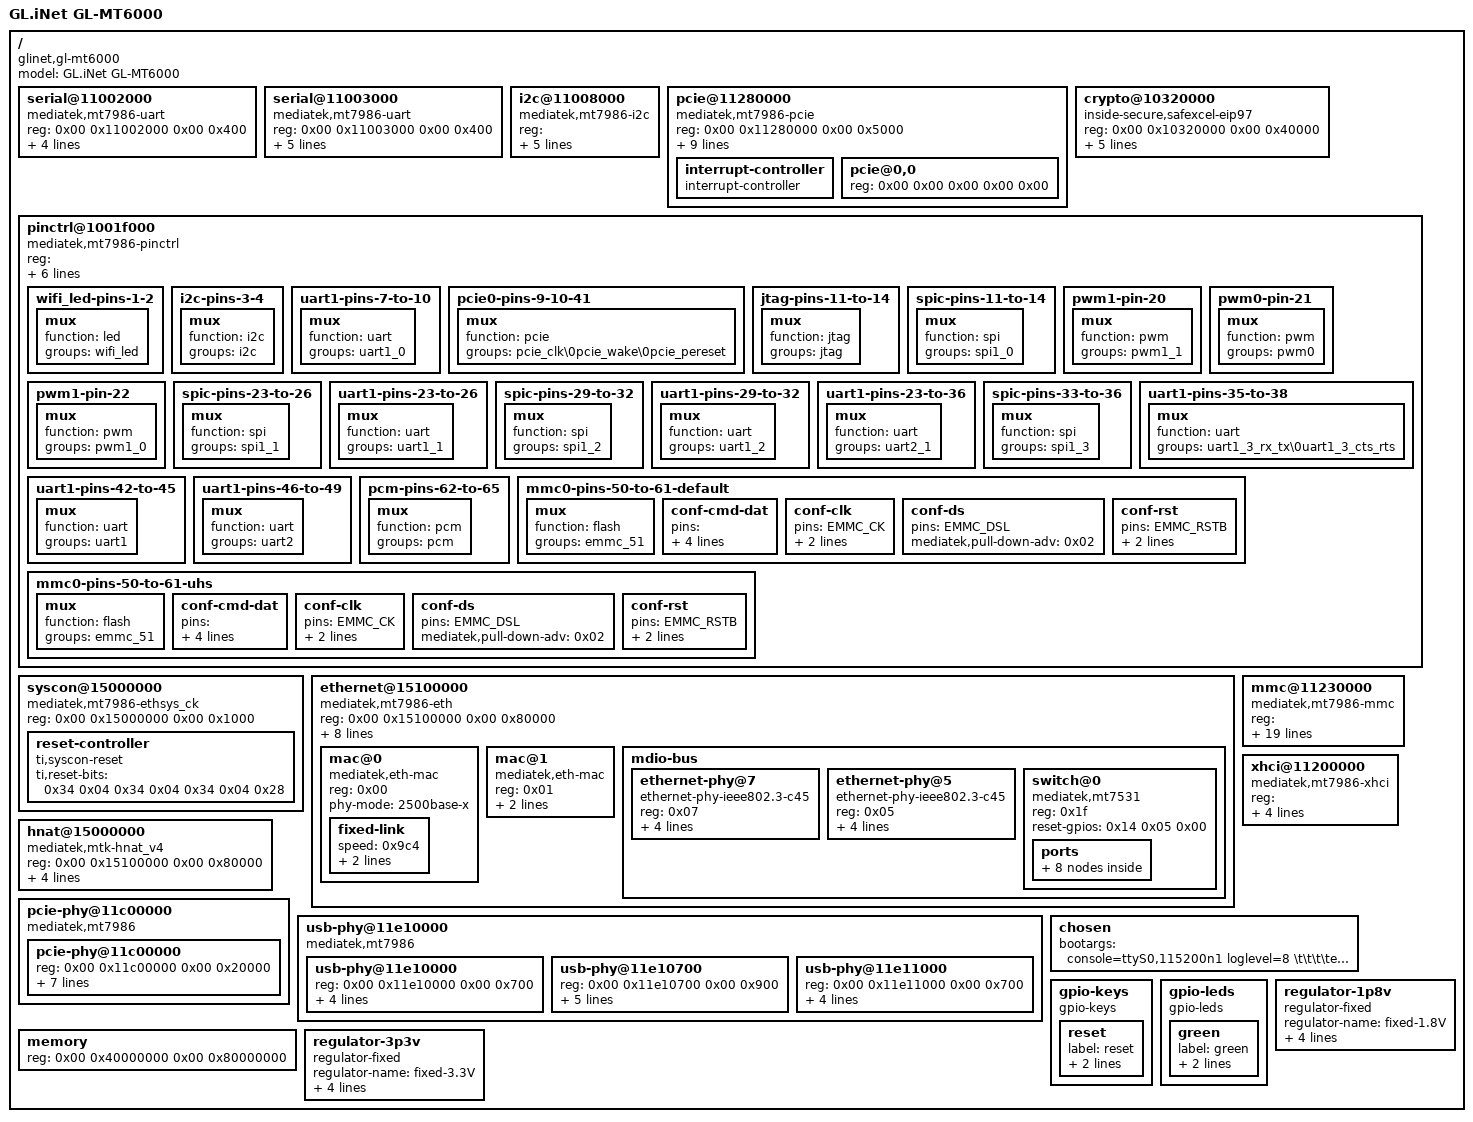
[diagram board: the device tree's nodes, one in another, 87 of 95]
/dts-v1/;
#include <dt-bindings/gpio/gpio.h>     
#include <dt-bindings/input/input.h>   
#include <dt-bindings/pinctrl/mt65xx.h>
                                       
#include "mt7986a.dtsi"                

  
/ {
	model = "GL.iNet GL-MT6000";
	compatible = "glinet,gl-mt6000", "mediatek,mt7986a";

	serial@11002000 {
		compatible = "mediatek,mt7986-uart\0mediatek,mt6577-uart";
		reg = <0x00 0x11002000 0x00 0x400>;
		interrupts = <0x00 0x7b 0x04>;
		clocks = <0x04 0x1c>;
		assigned-clocks = <0x05 0x3b 0x04 0x00>;
		assigned-clock-parents = <0x05 0x00 0x03 0x01>;
		status = "okay";
	};

	serial@11003000 {
		compatible = "mediatek,mt7986-uart\0mediatek,mt6577-uart";
		reg = <0x00 0x11003000 0x00 0x400>;
		interrupts = <0x00 0x7c 0x04>;
		clocks = <0x04 0x1d>;
		assigned-clocks = <0x04 0x01>;
		assigned-clock-parents = <0x03 0x00>;
		status = "okay";
		pinctrl-names = "default";
		pinctrl-0 = <0x07>;
	};

	i2c@11008000 {
		compatible = "mediatek,mt7986-i2c";
		reg = <0x00 0x11008000 0x00 0x90 0x00 0x10217080 0x00 0x80>;
		interrupts = <0x00 0x88 0x04>;
		clock-div = <0x05>;
		clocks = <0x04 0x1b 0x04 0x17>;
		clock-names = "main\0dma";
		#address-cells = <0x01>;
		#size-cells = <0x00>;
		status = "okay";
		pinctrl-names = "default";
		pinctrl-0 = <0x08>;
	};

	pcie@11280000 {
		compatible = "mediatek,mt7986-pcie";
		reg = <0x00 0x11280000 0x00 0x5000>;
		reg-names = "pcie-mac";
		#address-cells = <0x03>;
		#size-cells = <0x02>;
		interrupts = <0x00 0xa8 0x04>;
		bus-range = <0x00 0xff>;
		ranges = <0x82000000 0x00 0x20000000 0x00 0x20000000 0x00 0x10000000>;
		status = "okay";
		clocks = <0x04 0x08 0x04 0x32 0x04 0x33 0x04 0x34 0x04 0x35>;
		phys = <0x11 0x02>;
		phy-names = "pcie-phy";
		#interrupt-cells = <0x01>;
		interrupt-map-mask = <0x00 0x00 0x00 0x07>;
		interrupt-map = <0x00 0x00 0x00 0x01 0x12 0x00 0x00 0x00 0x00 0x02 0x12 0x01 0x00 0x00 0x00 0x03 0x12 0x02 0x00 0x00 0x00 0x04 0x12 0x03>;
		pinctrl-names = "default";
		pinctrl-0 = <0x13>;

		interrupt-controller {
			interrupt-controller;
			#address-cells = <0x00>;
			#interrupt-cells = <0x01>;
			phandle = <0x12>;
		};

		pcie@0,0 {
			reg = <0x00 0x00 0x00 0x00 0x00>;
		};
	};

	crypto@10320000 {
		compatible = "inside-secure,safexcel-eip97";
		reg = <0x00 0x10320000 0x00 0x40000>;
		interrupts = <0x00 0x74 0x04 0x00 0x75 0x04 0x00 0x76 0x04 0x00 0x77 0x04>;
		interrupt-names = "ring0\0ring1\0ring2\0ring3";
		clocks = <0x04 0x0f>;
		clock-names = "infra_eip97_ck";
		assigned-clocks = <0x05 0x50>;
		assigned-clock-parents = <0x05 0x15>;
	};

	pinctrl@1001f000 {
		compatible = "mediatek,mt7986-pinctrl";
		reg = <0x00 0x1001f000 0x00 0x1000 0x00 0x11c30000 0x00 0x1000 0x00 0x11c40000 0x00 0x1000 0x00 0x11e20000 0x00 0x1000 0x00 0x11e30000 0x00 0x1000 0x00 0x11f00000 0x00 0x1000 0x00 0x11f10000 0x00 0x1000 0x00 0x1000b000 0x00 0x1000>;
		reg-names = "gpio_base\0iocfg_rt_base\0iocfg_rb_base\0iocfg_lt_base\0iocfg_lb_base\0iocfg_tr_base\0iocfg_tl_base\0eint";
		gpio-controller;
		#gpio-cells = <0x02>;
		gpio-ranges = <0x14 0x00 0x00 0x64>;
		interrupt-controller;
		interrupts = <0x00 0xe1 0x04>;
		interrupt-parent = <0x01>;
		#interrupt-cells = <0x02>;
		phandle = <0x14>;

		wifi_led-pins-1-2 {

			mux {
				function = "led";
				groups = "wifi_led";
			};
		};

		i2c-pins-3-4 {
			phandle = <0x08>;

			mux {
				function = "i2c";
				groups = "i2c";
			};
		};

		uart1-pins-7-to-10 {

			mux {
				function = "uart";
				groups = "uart1_0";
			};
		};

		pcie0-pins-9-10-41 {
			phandle = <0x13>;

			mux {
				function = "pcie";
				groups = "pcie_clk\0pcie_wake\0pcie_pereset";
			};
		};

		jtag-pins-11-to-14 {

			mux {
				function = "jtag";
				groups = "jtag";
			};
		};

		spic-pins-11-to-14 {

			mux {
				function = "spi";
				groups = "spi1_0";
			};
		};

		pwm1-pin-20 {

			mux {
				function = "pwm";
				groups = "pwm1_1";
			};
		};

		pwm0-pin-21 {
			phandle = <0x06>;

			mux {
				function = "pwm";
				groups = "pwm0";
			};
		};

		pwm1-pin-22 {

			mux {
				function = "pwm";
				groups = "pwm1_0";
			};
		};

		spic-pins-23-to-26 {

			mux {
				function = "spi";
				groups = "spi1_1";
			};
		};

		uart1-pins-23-to-26 {

			mux {
				function = "uart";
				groups = "uart1_1";
			};
		};

		spic-pins-29-to-32 {
			phandle = <0x1d>;

			mux {
				function = "spi";
				groups = "spi1_2";
			};
		};

		uart1-pins-29-to-32 {

			mux {
				function = "uart";
				groups = "uart1_2";
			};
		};

		uart1-pins-23-to-36 {

			mux {
				function = "uart";
				groups = "uart2_1";
			};
		};

		spic-pins-33-to-36 {

			mux {
				function = "spi";
				groups = "spi1_3";
			};
		};

		uart1-pins-35-to-38 {

			mux {
				function = "uart";
				groups = "uart1_3_rx_tx\0uart1_3_cts_rts";
			};
		};

		uart1-pins-42-to-45 {
			phandle = <0x07>;

			mux {
				function = "uart";
				groups = "uart1";
			};
		};

		uart1-pins-46-to-49 {

			mux {
				function = "uart";
				groups = "uart2";
			};
		};

		pcm-pins-62-to-65 {

			mux {
				function = "pcm";
				groups = "pcm";
			};
		};

		mmc0-pins-50-to-61-default {
			phandle = <0x1e>;

			mux {
				function = "flash";
				groups = "emmc_51";
			};

			conf-cmd-dat {
				pins = "EMMC_DATA_0\0EMMC_DATA_1\0EMMC_DATA_2\0EMMC_DATA_3\0EMMC_DATA_4\0EMMC_DATA_5\0EMMC_DATA_6\0EMMC_DATA_7\0EMMC_CMD";
				input-enable;
				drive-strength = <0x04>;
				mediatek,pull-up-adv = <0x01>;
			};

			conf-clk {
				pins = "EMMC_CK";
				drive-strength = <0x06>;
				mediatek,pull-down-adv = <0x02>;
			};

			conf-ds {
				pins = "EMMC_DSL";
				mediatek,pull-down-adv = <0x02>;
			};

			conf-rst {
				pins = "EMMC_RSTB";
				drive-strength = <0x04>;
				mediatek,pull-up-adv = <0x01>;
			};
		};

		mmc0-pins-50-to-61-uhs {
			phandle = <0x1f>;

			mux {
				function = "flash";
				groups = "emmc_51";
			};

			conf-cmd-dat {
				pins = "EMMC_DATA_0\0EMMC_DATA_1\0EMMC_DATA_2\0EMMC_DATA_3\0EMMC_DATA_4\0EMMC_DATA_5\0EMMC_DATA_6\0EMMC_DATA_7\0EMMC_CMD";
				input-enable;
				drive-strength = <0x04>;
				mediatek,pull-up-adv = <0x01>;
			};

			conf-clk {
				pins = "EMMC_CK";
				drive-strength = <0x06>;
				mediatek,pull-down-adv = <0x02>;
			};

			conf-ds {
				pins = "EMMC_DSL";
				mediatek,pull-down-adv = <0x02>;
			};

			conf-rst {
				pins = "EMMC_RSTB";
				drive-strength = <0x04>;
				mediatek,pull-up-adv = <0x01>;
			};
		};
	};

	syscon@15000000 {
		#address-cells = <0x01>;
		#size-cells = <0x01>;
		compatible = "mediatek,mt7986-ethsys_ck\0syscon";
		reg = <0x00 0x15000000 0x00 0x1000>;
		#clock-cells = <0x01>;
		#reset-cells = <0x01>;
		phandle = <0x15>;

		reset-controller {
			compatible = "ti,syscon-reset";
			#reset-cells = <0x01>;
			ti,reset-bits = <0x34 0x04 0x34 0x04 0x34 0x04 0x28>;
			phandle = <0x02>;
		};
	};

	ethernet@15100000 {
		compatible = "mediatek,mt7986-eth";
		reg = <0x00 0x15100000 0x00 0x80000>;
		interrupts = <0x00 0xbd 0x04 0x00 0xbe 0x04 0x00 0xbf 0x04 0x00 0xc0 0x04 0x00 0xc4 0x04 0x00 0xc5 0x04 0x00 0xc6 0x04 0x00 0xc7 0x04>;
		clocks = <0x15 0x00 0x15 0x01 0x15 0x02 0x15 0x03 0x15 0x04 0x16 0x00 0x16 0x01 0x16 0x02 0x16 0x03 0x17 0x00 0x17 0x01 0x17 0x02 0x17 0x03>;
		clock-names = "fe\0gp2\0gp1\0wocpu1\0wocpu0\0sgmii_tx250m\0sgmii_rx250m\0sgmii_cdr_ref\0sgmii_cdr_fb\0sgmii2_tx250m\0sgmii2_rx250m\0sgmii2_cdr_ref\0sgmii2_cdr_fb";
		assigned-clocks = <0x05 0x4b 0x05 0x4c>;
		assigned-clock-parents = <0x05 0x15 0x05 0x1b>;
		mediatek,ethsys = <0x15>;
		mediatek,sgmiisys = <0x16 0x17>;
		#reset-cells = <0x01>;
		#address-cells = <0x01>;
		#size-cells = <0x00>;
		status = "okay";

		mac@0 {
			compatible = "mediatek,eth-mac";
			reg = <0x00>;
			phy-mode = "2500base-x";
			phandle = <0x1a>;

			fixed-link {
				speed = <0x9c4>;
				full-duplex;
				pause;
			};
		};

		mac@1 {
			compatible = "mediatek,eth-mac";
			reg = <0x01>;
			phy-mode = "2500base-x";
			phy-handle = <0x18>;
		};

		mdio-bus {
			#address-cells = <0x01>;
			#size-cells = <0x00>;

			ethernet-phy@7 {
				compatible = "ethernet-phy-ieee802.3-c45";
				reg = <0x07>;
				reset-gpios = <0x14 0x06 0x01>;
				reset-assert-us = <0x186a0>;
				reset-deassert-us = <0x186a0>;
				phy-mode = "2500base-x";
				phandle = <0x18>;
			};

			ethernet-phy@5 {
				compatible = "ethernet-phy-ieee802.3-c45";
				reg = <0x05>;
				reset-gpios = <0x14 0x30 0x01>;
				reset-assert-us = <0x186a0>;
				reset-deassert-us = <0x186a0>;
				phy-mode = "2500base-x";
				phandle = <0x19>;
			};

			switch@0 {
				compatible = "mediatek,mt7531";
				reg = <0x1f>;
				reset-gpios = <0x14 0x05 0x00>;

				ports {
					#address-cells = <0x01>;
					#size-cells = <0x00>;

					port@0 {
						reg = <0x00>;
						label = "lan0";
					};

					port@1 {
						reg = <0x01>;
						label = "lan1";
					};

					port@2 {
						reg = <0x02>;
						label = "lan2";
					};

					port@3 {
						reg = <0x03>;
						label = "lan3";
					};

					port@4 {
						reg = <0x04>;
						label = "lan4";
					};

					port@5 {
						reg = <0x05>;
						label = "lan5";
						phy-mode = "2500base-x";
						phy-handle = <0x19>;
					};

					port@6 {
						reg = <0x06>;
						label = "cpu";
						ethernet = <0x1a>;
						phy-mode = "2500base-x";

						fixed-link {
							speed = <0x9c4>;
							full-duplex;
							pause;
						};
					};
				};
			};
		};
	};

	hnat@15000000 {
		compatible = "mediatek,mtk-hnat_v4";
		reg = <0x00 0x15100000 0x00 0x80000>;
		resets = <0x15 0x00>;
		reset-names = "mtketh";
		status = "okay";
		mtketh-wan = "eth1";
		mtketh-lan = "lan";
		mtketh-max-gmac = <0x02>;
	};

	mmc@11230000 {
		compatible = "mediatek,mt7986-mmc";
		reg = <0x00 0x11230000 0x00 0x1000 0x00 0x11c20000 0x00 0x1000>;
		interrupts = <0x00 0x8f 0x04>;
		clocks = <0x05 0x28 0x04 0x28 0x04 0x27 0x04 0x2a 0x04 0x29>;
		clock-names = "source\0hclk\0source_cg\0sys_cg\0axi_cg";
		assigned-clocks = <0x05 0x40 0x05 0x3f>;
		assigned-clock-parents = <0x05 0x01 0x05 0x11>;
		status = "okay";
		pinctrl-names = "default\0state_uhs";
		pinctrl-0 = <0x1e>;
		pinctrl-1 = <0x1f>;
		bus-width = <0x08>;
		max-frequency = <0xbebc200>;
		cap-mmc-highspeed;
		mmc-hs200-1_8v;
		mmc-hs400-1_8v;
		hs400-ds-delay = <0x14014>;
		vmmc-supply = <0x20>;
		vqmmc-supply = <0x21>;
		non-removable;
		no-sd;
		no-sdio;
	};

	xhci@11200000 {
		compatible = "mediatek,mt7986-xhci\0mediatek,mtk-xhci";
		reg = <0x00 0x11200000 0x00 0x2e00 0x00 0x11203e00 0x00 0x100>;
		reg-names = "mac\0ippc";
		interrupts = <0x00 0xad 0x04>;
		phys = <0x22 0x03 0x23 0x04 0x24 0x03>;
		clocks = <0x25 0x25 0x25 0x25 0x25>;
		clock-names = "sys_ck\0xhci_ck\0ref_ck\0mcu_ck\0dma_ck";
		#address-cells = <0x02>;
		#size-cells = <0x02>;
		status = "okay";
	};

	pcie-phy@11c00000 {
		compatible = "mediatek,mt7986\0mediatek,generic-tphy-v4";
		#address-cells = <0x02>;
		#size-cells = <0x02>;
		ranges;
		status = "okay";

		pcie-phy@11c00000 {
			reg = <0x00 0x11c00000 0x00 0x20000>;
			clocks = <0x25>;
			clock-names = "ref";
			#phy-cells = <0x01>;
			auto_load_valid;
			auto_load_valid_ln1;
			nvmem-cells = <0x26 0x27 0x28 0x29 0x2a 0x2b 0x2c 0x2d>;
			nvmem-cell-names = "intr\0rx_imp\0tx_imp\0auto_load_valid\0intr_ln1\0rx_imp_ln1\0tx_imp_ln1\0auto_load_valid_ln1";
			status = "okay";
			phandle = <0x11>;
		};
	};

	usb-phy@11e10000 {
		compatible = "mediatek,mt7986\0mediatek,generic-tphy-v2";
		#address-cells = <0x02>;
		#size-cells = <0x02>;
		ranges;
		status = "okay";

		usb-phy@11e10000 {
			reg = <0x00 0x11e10000 0x00 0x700>;
			clocks = <0x25>;
			clock-names = "ref";
			#phy-cells = <0x01>;
			auto_load_valid;
			nvmem-cells = <0x2e 0x2f>;
			nvmem-cell-names = "intr\0auto_load_valid";
			status = "okay";
			phandle = <0x22>;
		};

		usb-phy@11e10700 {
			reg = <0x00 0x11e10700 0x00 0x900>;
			clocks = <0x25>;
			clock-names = "ref";
			#phy-cells = <0x01>;
			auto_load_valid;
			nvmem-cells = <0x30 0x31 0x32 0x33>;
			nvmem-cell-names = "intr\0rx_imp\0tx_imp\0auto_load_valid";
			status = "okay";
			phandle = <0x23>;
		};

		usb-phy@11e11000 {
			reg = <0x00 0x11e11000 0x00 0x700>;
			clocks = <0x25>;
			clock-names = "ref";
			#phy-cells = <0x01>;
			auto_load_valid;
			nvmem-cells = <0x34 0x35>;
			nvmem-cell-names = "intr\0auto_load_valid";
			status = "okay";
			phandle = <0x24>;
		};
	};

	chosen {
		bootargs = "console=ttyS0,115200n1 loglevel=8  \t\t\t\tearlycon=uart8250,mmio32,0x11002000 \t\t\t\troot=PARTLABEL=rootfs rootwait rootfstype=squashfs,f2fs";
	};

	gpio-keys {
		compatible = "gpio-keys";

		reset {
			label = "reset";
			linux,code = <0x198>;
			gpios = <0x14 0x10 0x01>;
		};
	};

	gpio-leds {
		compatible = "gpio-leds";

		green {
			label = "green";
			gpios = <0x14 0x16 0x01>;
			default-state = "off";
		};
	};

	memory {
		reg = <0x00 0x40000000 0x00 0x80000000>;
	};

	regulator-1p8v {
		compatible = "regulator-fixed";
		regulator-name = "fixed-1.8V";
		regulator-min-microvolt = <0x1b7740>;
		regulator-max-microvolt = <0x1b7740>;
		regulator-boot-on;
		regulator-always-on;
		phandle = <0x21>;
	};

	regulator-3p3v {
		compatible = "regulator-fixed";
		regulator-name = "fixed-3.3V";
		regulator-min-microvolt = <0x325aa0>;
		regulator-max-microvolt = <0x325aa0>;
		regulator-boot-on;
		regulator-always-on;
		phandle = <0x20>;
	};
};
